# iND83213A register map
Vendor: Indiemicro; Series: Rugby; File version: 1.0
CPU: CM0 r0p1, selectable endian, no MPU, no FPU, 4 interrupt priority bits
Registers are 32-bit, read-write, no defined reset value unless marked. A register's access mark holds for its fields unless they carry their own. Offsets are from the block's base; [hi:lo] are bit positions; {n}, {i} and the like mark numbered series.

## GPIO — GPIO bit control and configuration
Base 0x50014000; register names take the prefix GPIO_
0x00 GPADATA — GPIO Port A Data
  [7:0] GPADATA1024 — Port A data. To aid in the efficiency of software, the GPIO ports allow for the modification of individual bits in the GPIO Data by using bits [9:2] of the address bus as a enable. In this manner, software drivers can modify individual GPIO pins in a single instruction without affecting the state of the other pins. This method is more efficient than the conventional method of performing a read-modify-write operation to set or clear an individual GPIO pin. To write all the bits at the same time use address offset of 0x07F.
0x400 GPBDATA — GPIO Port B Data
  [2:0] GPBDATA1024 — Port B data.
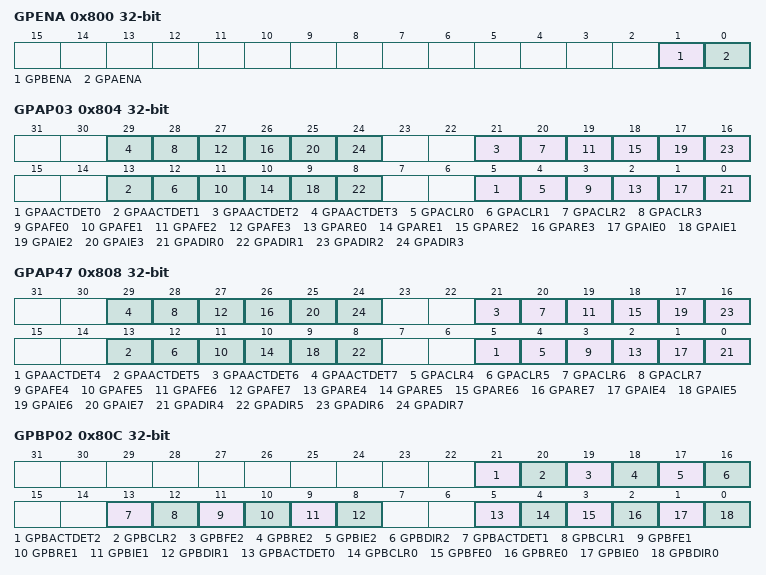
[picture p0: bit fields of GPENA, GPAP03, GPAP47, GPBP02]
0x800 GPENA — GPIO Port Enables
  [1] GPBENA — Enables the Clock-Gate, can be cleared to save power, if none of the GPIO functionality is required
  [0] GPAENA — Enables the Clock-Gate, can be cleared to save power, if none of the GPIO functionality is required
0x804 GPAP03 — GPIO Port A Pin 0-3 Control
  [8n+5] GPAACTDET{n} ro (n=0..3) — Pin {n} activity interrupt.
  [8n+4] GPACLR{n} wo (n=0..3) — Pin {n} interrupt clear. Autoclear: includes a synchronous reset signal which clears the register on the cycle following write.
  [8n+3] GPAFE{n} (n=0..3) — Pin {n} falling edge enable.
  [8n+2] GPARE{n} (n=0..3) — Pin {n} rising edge enable.
  [8n+1] GPAIE{n} (n=0..3) — Pin {n} interrupt enable.
  [8n] GPADIR{n} (n=0..3) — Pin {n} output enable.
0x808 GPAP47 — GPIO Port A Pin 4-7 Control
  [8n-27] GPAACTDET{n} ro (n=4..7) — Pin {n} activity interrupt.
  [8n-28] GPACLR{n} wo (n=4..7) — Pin {n} interrupt clear. Autoclear: includes a synchronous reset signal which clears the register on the cycle following write.
  [8n-29] GPAFE{n} (n=4..7) — Pin {n} falling edge enable.
  [8n-30] GPARE{n} (n=4..7) — Pin {n} rising edge enable.
  [8n-31] GPAIE{n} (n=4..7) — Pin {n} interrupt enable.
  [8n-32] GPADIR{n} (n=4..7) — Pin {n} output enable.
0x80C GPBP02 — GPIO Port B Pin 0-2 Control
  [21] GPBACTDET2 ro — Pin 2 activity interrupt.
  [20] GPBCLR2 wo — Pin 2 interrupt clear. Autoclear: includes a synchronous reset signal which clears the register on the cycle following write.
  [19] GPBFE2 — Pin 2 falling edge enable.
  [18] GPBRE2 — Pin 2 rising edge enable.
  [17] GPBIE2 — Pin 2 interrupt enable.
  [16] GPBDIR2 — Pin 2 output enable.
  [13] GPBACTDET1 ro — Pin 1 activity interrupt.
  [12] GPBCLR1 wo — Pin 1 interrupt clear. Autoclear: includes a synchronous reset signal which clears the register on the cycle following write.
  [11] GPBFE1 — Pin 1 falling edge enable.
  [10] GPBRE1 — Pin 1 rising edge enable.
  [9] GPBIE1 — Pin 1 interrupt enable.
  [8] GPBDIR1 — Pin 1 output enable.
  [5] GPBACTDET0 ro — Pin 0 activity interrupt.
  [4] GPBCLR0 wo — Pin 0 interrupt clear. Autoclear: includes a synchronous reset signal which clears the register on the cycle following write.
  [3] GPBFE0 — Pin 0 falling edge enable.
  [2] GPBRE0 — Pin 0 rising edge enable.
  [1] GPBIE0 — Pin 0 interrupt enable.
  [0] GPBDIR0 — Pin 0 output enable.

## TIMER0 — General purpose timer 0 registers
Base 0x50020000; register names take the prefix TIMER0_
0x00 COUNT — Timer Counter Register
  [31:0] COUNT — Count. Initial counter value. The timer will count from this value to 0xFFFFFFFF and roll over to 0x00000000. At this point it will generate an interrupt if enabled. The interrupt routine is responsible for reloading the value if needed as this timer does not auto-reload the original content.
0x04 CFG — Timer Control Register
  [0] ENA — Enable. This bit starts/stops the timer: 1 = Timer Running 0 = Timer Inactive

## TIMER1 — General purpose timer 1 registers
Base 0x50020008; register names take the prefix TIMER1_
Registers as TIMER0.

## TIMER2 — General purpose timer 2 registers
Base 0x50020010; register names take the prefix TIMER2_
Registers as TIMER0.

## WDT1 — The watchdog timer that is local to VERNE MCU
Base 0x50020018; register names take the prefix WDT1_
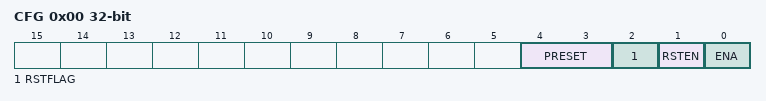
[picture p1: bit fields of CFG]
0x00 CFG — Config
  [4:3] PRESET — Preset. Defines the watchdog timeout period. It means that the WDT internal counter will count from 0 to the prescaler value at the system clock speed and trigger if not cleared. For instance, a system running from a 30MHz Crystal with WDTPRES[1I0] = 10 will trigger the WDT after approximately 0.14 seconds if not cleared properly and in time by the application. 0x0: 2^13 / System Clock 0x1: 2^19 / System Clock 0x2: 2^22 / System Clock 0x3: 2^32 / System Clock
  [2] RSTFLAG — Reset flag. This flag is set by the system at the initialization if the initialization was caused by a reset triggered by the WDT. The bit can be cleared by the application.
  [1] RSTEN — Reset enable. If enabled a WDT time-out will force the microcontroller to reset. This bit can be asserted but it cannot be de-asserted.
  [0] ENA — WDT Enable. This bit can be asserted but it cannot be de-asserted. It means that once the WDT is enabled it cannot be turned off until a Reset or Power-On Reset occurs.
0x04 KEY
  [31:0] KEY — Key. To clear the WDT counting the following words must be written in this order and without any other instruction between then: 0x3C570001 0x007F4AD6
